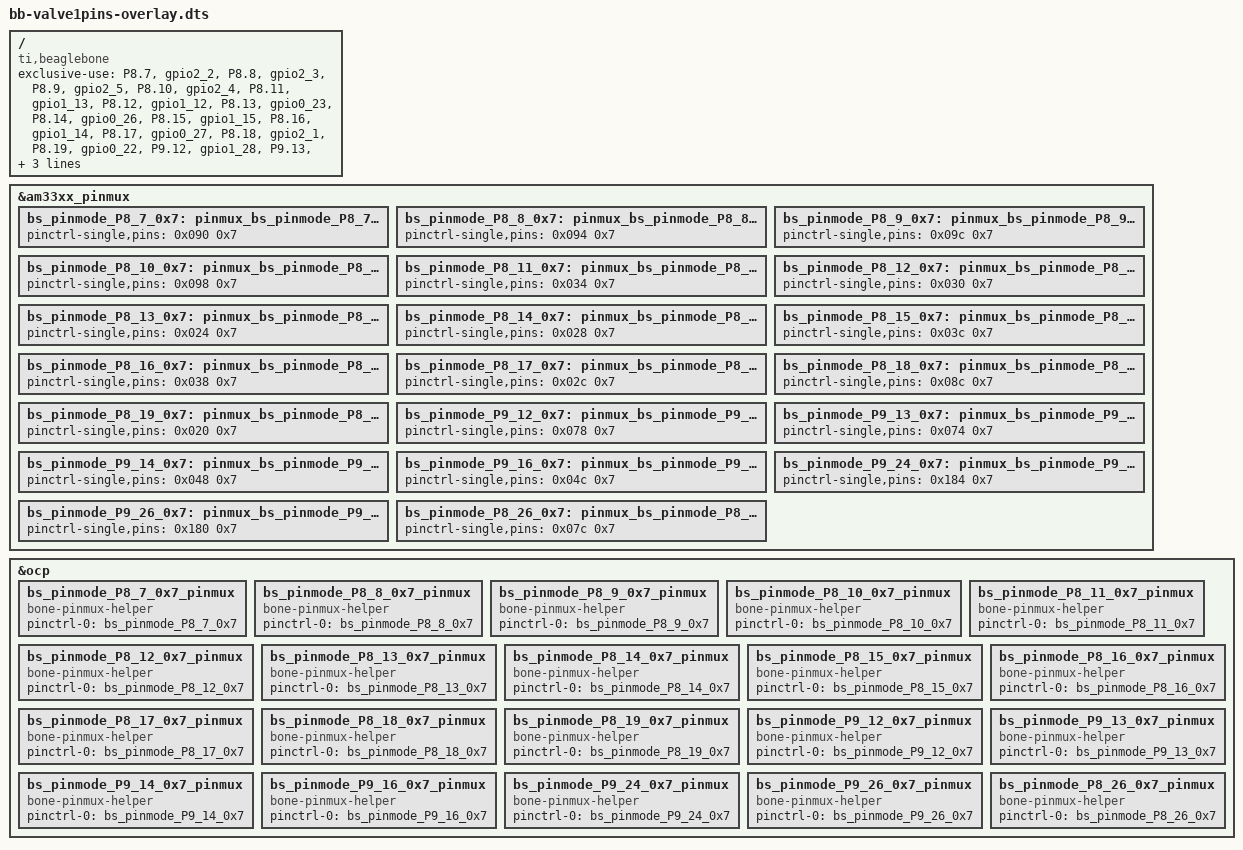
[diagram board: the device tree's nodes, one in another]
/dts-v1/;
/plugin/;

/ {
    compatible = "ti,beaglebone", "ti,beaglebone-black";

    /* Add exclusive-use for each pin */
    exclusive-use =
        /* Pin P8.7 */
        "P8.7", "gpio2_2",

        /* Pin P8.8 */
        "P8.8", "gpio2_3",

        /* Pin P8.9 */
        "P8.9", "gpio2_5",

        /* Pin P8.10 */
        "P8.10", "gpio2_4",

        /* Pin P8.11 */
        "P8.11", "gpio1_13",

        /* Pin P8.12 */
        "P8.12", "gpio1_12",

        /* Pin P8.13 */
        "P8.13", "gpio0_23",

        /* Pin P8.14 */
        "P8.14", "gpio0_26",

        /* Pin P8.15 */
        "P8.15", "gpio1_15",

        /* Pin P8.16 */
        "P8.16", "gpio1_14",

        /* Pin P8.17 */
        "P8.17", "gpio0_27",

        /* Pin P8.18 */
        "P8.18", "gpio2_1",

        /* Pin P8.19 */
        "P8.19", "gpio0_22",

        "P9.12", "gpio1_28",
        "P9.13", "gpio0_31",
        "P9.14", "gpio1_18",
        "P9.16", "gpio1_19",
        "P9.24", "gpio0_15",
        "P9.26", "gpio0_14",
        "P8.26", "gpio1_29";

    /* Add the pinmux configurations for each pin */
    fragment@0 {
        target = <&am33xx_pinmux>;
        __overlay__ {
            bs_pinmode_P8_7_0x7: pinmux_bs_pinmode_P8_7_0x7 {
                pinctrl-single,pins = <0x090 0x7>;
            };
            bs_pinmode_P8_8_0x7: pinmux_bs_pinmode_P8_8_0x7 {
                pinctrl-single,pins = <0x094 0x7>;
            };
            bs_pinmode_P8_9_0x7: pinmux_bs_pinmode_P8_9_0x7 {
                pinctrl-single,pins = <0x09c 0x7>;
            };
            bs_pinmode_P8_10_0x7: pinmux_bs_pinmode_P8_10_0x7 {
                pinctrl-single,pins = <0x098 0x7>;
            };
            bs_pinmode_P8_11_0x7: pinmux_bs_pinmode_P8_11_0x7 {
                pinctrl-single,pins = <0x034 0x7>;
            };
            bs_pinmode_P8_12_0x7: pinmux_bs_pinmode_P8_12_0x7 {
                pinctrl-single,pins = <0x030 0x7>;
            };
            bs_pinmode_P8_13_0x7: pinmux_bs_pinmode_P8_13_0x7 {
                pinctrl-single,pins = <0x024 0x7>;
            };
            bs_pinmode_P8_14_0x7: pinmux_bs_pinmode_P8_14_0x7 {
                pinctrl-single,pins = <0x028 0x7>;
            };
            bs_pinmode_P8_15_0x7: pinmux_bs_pinmode_P8_15_0x7 {
                pinctrl-single,pins = <0x03c 0x7>;
            };
            bs_pinmode_P8_16_0x7: pinmux_bs_pinmode_P8_16_0x7 {
                pinctrl-single,pins = <0x038 0x7>;
            };
            bs_pinmode_P8_17_0x7: pinmux_bs_pinmode_P8_17_0x7 {
                pinctrl-single,pins = <0x02c 0x7>;
            };
            bs_pinmode_P8_18_0x7: pinmux_bs_pinmode_P8_18_0x7 {
                pinctrl-single,pins = <0x08c 0x7>;
            };
            bs_pinmode_P8_19_0x7: pinmux_bs_pinmode_P8_19_0x7 {
                pinctrl-single,pins = <0x020 0x7>;
            };

            bs_pinmode_P9_12_0x7: pinmux_bs_pinmode_P9_12_0x7 {
                pinctrl-single,pins = <0x078 0x7>;
            };
            bs_pinmode_P9_13_0x7: pinmux_bs_pinmode_P9_13_0x7 {
                pinctrl-single,pins = <0x074 0x7>;
            };
            bs_pinmode_P9_14_0x7: pinmux_bs_pinmode_P9_14_0x7 {
                pinctrl-single,pins = <0x048 0x7>;
            };
            bs_pinmode_P9_16_0x7: pinmux_bs_pinmode_P9_16_0x7 {
                pinctrl-single,pins = <0x04c 0x7>;
            };
            bs_pinmode_P9_24_0x7: pinmux_bs_pinmode_P9_24_0x7 {
                pinctrl-single,pins = <0x184 0x7>;
            };
            bs_pinmode_P9_26_0x7: pinmux_bs_pinmode_P9_26_0x7 {
                pinctrl-single,pins = <0x180 0x7>;
            };
            bs_pinmode_P8_26_0x7: pinmux_bs_pinmode_P8_26_0x7 {
                pinctrl-single,pins = <0x07c 0x7>;
            };
        };
    };

    /* Add pinmux helper configurations for each pin */
    fragment@1 {
        target = <&ocp>;
        __overlay__ {
            bs_pinmode_P8_7_0x7_pinmux {
                compatible = "bone-pinmux-helper";
                status = "okay";
                pinctrl-names = "default";
                pinctrl-0 = <&bs_pinmode_P8_7_0x7>;
            };
            bs_pinmode_P8_8_0x7_pinmux {
                compatible = "bone-pinmux-helper";
                status = "okay";
                pinctrl-names = "default";
                pinctrl-0 = <&bs_pinmode_P8_8_0x7>;
            };
            bs_pinmode_P8_9_0x7_pinmux {
                compatible = "bone-pinmux-helper";
                status = "okay";
                pinctrl-names = "default";
                pinctrl-0 = <&bs_pinmode_P8_9_0x7>;
            };
            bs_pinmode_P8_10_0x7_pinmux {
                compatible = "bone-pinmux-helper";
                status = "okay";
                pinctrl-names = "default";
                pinctrl-0 = <&bs_pinmode_P8_10_0x7>;
            };
            bs_pinmode_P8_11_0x7_pinmux {
                compatible = "bone-pinmux-helper";
                status = "okay";
                pinctrl-names = "default";
                pinctrl-0 = <&bs_pinmode_P8_11_0x7>;
            };
            bs_pinmode_P8_12_0x7_pinmux {
                compatible = "bone-pinmux-helper";
                status = "okay";
                pinctrl-names = "default";
                pinctrl-0 = <&bs_pinmode_P8_12_0x7>;
            };
            bs_pinmode_P8_13_0x7_pinmux {
                compatible = "bone-pinmux-helper";
                status = "okay";
                pinctrl-names = "default";
                pinctrl-0 = <&bs_pinmode_P8_13_0x7>;
            };
            bs_pinmode_P8_14_0x7_pinmux {
                compatible = "bone-pinmux-helper";
                status = "okay";
                pinctrl-names = "default";
                pinctrl-0 = <&bs_pinmode_P8_14_0x7>;
            };
            bs_pinmode_P8_15_0x7_pinmux {
                compatible = "bone-pinmux-helper";
                status = "okay";
                pinctrl-names = "default";
                pinctrl-0 = <&bs_pinmode_P8_15_0x7>;
            };
            bs_pinmode_P8_16_0x7_pinmux {
                compatible = "bone-pinmux-helper";
                status = "okay";
                pinctrl-names = "default";
                pinctrl-0 = <&bs_pinmode_P8_16_0x7>;
            };
            bs_pinmode_P8_17_0x7_pinmux {
                compatible = "bone-pinmux-helper";
                status = "okay";
                pinctrl-names = "default";
                pinctrl-0 = <&bs_pinmode_P8_17_0x7>;
            };
            bs_pinmode_P8_18_0x7_pinmux {
                compatible = "bone-pinmux-helper";
                status = "okay";
                pinctrl-names = "default";
                pinctrl-0 = <&bs_pinmode_P8_18_0x7>;
            };
            bs_pinmode_P8_19_0x7_pinmux {
                compatible = "bone-pinmux-helper";
                status = "okay";
                pinctrl-names = "default";
                pinctrl-0 = <&bs_pinmode_P8_19_0x7>;
            };

            bs_pinmode_P9_12_0x7_pinmux {
                compatible = "bone-pinmux-helper";
                status = "okay";
                pinctrl-names = "default";
                pinctrl-0 = <&bs_pinmode_P9_12_0x7>;
            };
            bs_pinmode_P9_13_0x7_pinmux {
                compatible = "bone-pinmux-helper";
                status = "okay";
                pinctrl-names = "default";
                pinctrl-0 = <&bs_pinmode_P9_13_0x7>;
            };
            bs_pinmode_P9_14_0x7_pinmux {
                compatible = "bone-pinmux-helper";
                status = "okay";
                pinctrl-names = "default";
                pinctrl-0 = <&bs_pinmode_P9_14_0x7>;
            };
            bs_pinmode_P9_16_0x7_pinmux {
                compatible = "bone-pinmux-helper";
                status = "okay";
                pinctrl-names = "default";
                pinctrl-0 = <&bs_pinmode_P9_16_0x7>;
            };
            bs_pinmode_P9_24_0x7_pinmux {
                compatible = "bone-pinmux-helper";
                status = "okay";
                pinctrl-names = "default";
                pinctrl-0 = <&bs_pinmode_P9_24_0x7>;
            };
            bs_pinmode_P9_26_0x7_pinmux {
                compatible = "bone-pinmux-helper";
                status = "okay";
                pinctrl-names = "default";
                pinctrl-0 = <&bs_pinmode_P9_26_0x7>;
            };
            bs_pinmode_P8_26_0x7_pinmux {
                compatible = "bone-pinmux-helper";
                status = "okay";
                pinctrl-names = "default";
                pinctrl-0 = <&bs_pinmode_P8_26_0x7>;
            };
        };
    };
};

